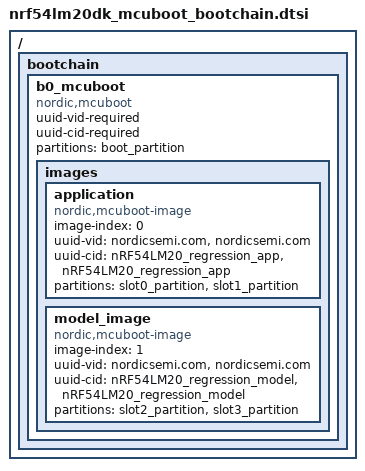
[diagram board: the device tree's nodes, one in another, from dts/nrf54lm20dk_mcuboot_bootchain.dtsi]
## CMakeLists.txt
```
#
# Copyright (c) 2025 Nordic Semiconductor ASA
#
# SPDX-License-Identifier: LicenseRef-Nordic-5-Clause
#

cmake_minimum_required(VERSION 3.20.0)

find_package(Zephyr REQUIRED HINTS $ENV{ZEPHYR_BASE})
project(nrf_edgeai_regression_sample)

include(${CMAKE_CURRENT_SOURCE_DIR}/../../../lib/model_ota/cmake/model_ota.cmake)

set(NEUTON_MODEL_DIR ${CMAKE_CURRENT_SOURCE_DIR}/src/nrf_edgeai_generated/Neuton)
set(AXON_MODEL_DIR ${CMAKE_CURRENT_SOURCE_DIR}/src/nrf_edgeai_generated/Axon)
set(NEUTON_MODEL_SRC ${NEUTON_MODEL_DIR}/nrf_edgeai_user_model.c)
set(AXON_MODEL_SRC ${AXON_MODEL_DIR}/nrf_edgeai_user_model.c)
set(AXON_MODEL_HEADER ${AXON_MODEL_DIR}/nrf_edgeai_user_model_axon.h)

target_include_directories(app PRIVATE include)

if(CONFIG_NRF_EDGEAI_REGRESSION_MODEL_AXON)
  if(NOT CONFIG_APP_MODEL_OTA)
    target_sources(app PRIVATE ${AXON_MODEL_SRC})
  endif()
  message(STATUS "Using Axon Edge AI model")
  target_include_directories(app PRIVATE ${AXON_MODEL_DIR})
else()
  if(NOT CONFIG_APP_MODEL_OTA)
    target_sources(app PRIVATE ${NEUTON_MODEL_SRC})
  endif()
  message(STATUS "Using Neuton Edge AI model")
  target_include_directories(app PRIVATE ${NEUTON_MODEL_DIR})
endif()

target_sources(app PRIVATE src/main.c)

if(CONFIG_APP_MODEL_OTA)
  if(CONFIG_NRF_EDGEAI_REGRESSION_MODEL_AXON)
    model_ota_edgeai_axon_model(
      TARGET regression
      SOLUTION_ID 36025
      MODEL_SRC ${AXON_MODEL_SRC}
      HEADER ${AXON_MODEL_HEADER}
      NAME regression
      VERSION 1.0.0
      PARTITION_NODELABEL model_storage
      UUID_CID nRF54LM20_regression_model
      UUID_VID nordicsemi.com
    )
  else()
    model_ota_edgeai_neuton_model(
      TARGET regression
      SOLUTION_ID 90508
      MODEL_SRC ${NEUTON_MODEL_SRC}
      PARTITION_NODELABEL model_storage
      NEURONS_CAP 2
      NAME regression
      VERSION 1.0.0
      UUID_CID nRF54LM20_regression_model
      UUID_VID nordicsemi.com
    )
  endif()

  model_ota_finalize()
endif()
```

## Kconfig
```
#
# Copyright (c) 2026 Nordic Semiconductor ASA
#
# SPDX-License-Identifier: LicenseRef-Nordic-5-Clause
#

menu "nRF Edge AI Regression sample"

choice NRF_EDGEAI_REGRESSION_MODEL
	prompt "Regression model backend"
	default NRF_EDGEAI_REGRESSION_MODEL_AXON if SOC_NRF54LM20B
	default NRF_EDGEAI_REGRESSION_MODEL_NEUTON
	help
	  Select which model implementation to use for the air quality regression sample.
	  Neuton runs on CPU; Axon uses the NPU and is only available on nRF54L20 (nrf54lm20b).

config NRF_EDGEAI_REGRESSION_MODEL_NEUTON
	bool "Neuton (CPU)"
	help
	  Use the Neuton model. Works on all nRF Edge AI supported boards.

config NRF_EDGEAI_REGRESSION_MODEL_AXON
	bool "Axon (NPU)"
	depends on SOC_NRF54LM20B
	select NRF_AXON
	help
	  Use the Axon model. Only available on nRF54L20 (nrf54lm20b) with Axon NPU.

endchoice

config APP_MODEL_OTA
	bool "Load regression model from a separate flash partition (model-only OTA)"
	select FLASH
	select FLASH_MAP
	select CRC
	select MODEL_OTA
	select MODEL_OTA_SMP
	help
	  When enabled, this sample does not ship a compiled-in regression model.
	  At boot, the model is loaded and validated from the model_storage flash
	  partition instead - independently of the application image.

	  Set via sysbuild as SB_CONFIG_APP_MODEL_OTA (see sysbuild_model_ota.conf).

if APP_MODEL_OTA

config APP_MODEL_OTA_NEUTON
	def_bool y
	depends on NRF_EDGEAI_REGRESSION_MODEL_NEUTON
	select MODEL_OTA_NEUTON

config APP_MODEL_OTA_AXON
	def_bool y
	depends on NRF_EDGEAI_REGRESSION_MODEL_AXON
	select MODEL_OTA_AXON

endif # APP_MODEL_OTA

endmenu

source "Kconfig.zephyr"
```

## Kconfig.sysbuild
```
#
# Copyright (c) 2026 Nordic Semiconductor
#
# SPDX-License-Identifier: LicenseRef-Nordic-5-Clause
#

config APP_MODEL_OTA
	bool "Load regression model from a separate flash partition (model-only OTA)"
	default n
	depends on BOOTLOADER_MCUBOOT
	help
	  When enabled, the sample loads the regression model from model_storage at boot
	  instead of using a compiled-in model. Propagated to the regression image as
	  CONFIG_APP_MODEL_OTA.

source "share/sysbuild/Kconfig"
```

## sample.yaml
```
sample:
  description: Sample showing nRF Edge AI regression model usage and results interpretation.
  name: nRF Edge AI Regression Sample
tests:
  sample.edgeai_regression:
    sysbuild: true
    build_only: true
    platform_allow:
      - nrf54l15dk/nrf54l05/cpuapp
      - nrf54l15dk/nrf54l10/cpuapp
      - nrf54l15dk/nrf54l15/cpuapp
      - nrf54h20dk/nrf54h20/cpuapp
      - nrf54lm20dk/nrf54lm20a/cpuapp
      - nrf54lm20dk/nrf54lm20b/cpuapp
    integration_platforms:
      - nrf54l15dk/nrf54l05/cpuapp
      - nrf54l15dk/nrf54l10/cpuapp
      - nrf54l15dk/nrf54l15/cpuapp
      - nrf54h20dk/nrf54h20/cpuapp
      - nrf54lm20dk/nrf54lm20a/cpuapp
      - nrf54lm20dk/nrf54lm20b/cpuapp
    tags:
      - nrf_edgeai_sample_regression
  sample.edgeai_regression.nrf54lm20dk:
    sysbuild: true
    build_only: false
    harness: console
    harness_config:
      type: multi_line
      ordered: true
      regex:
        - "nRF Edge AI runtime version: 2.2.0"
        - "--- Testing Model Air Quality predictions ---"
        - "Air quality - Predicted:.*Expected:.*absolute error"
        - "========== All test cases completed =========="
    platform_allow:
      - nrf54lm20dk/nrf54lm20a/cpuapp
      - nrf54lm20dk/nrf54lm20b/cpuapp
    integration_platforms:
      - nrf54lm20dk/nrf54lm20a/cpuapp
      - nrf54lm20dk/nrf54lm20b/cpuapp
    timeout: 30
    tags:
      - nrf_edgeai_sample_regression
```

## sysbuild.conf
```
# Copyright (c) 2026 Nordic Semiconductor ASA
#
# SPDX-License-Identifier: LicenseRef-Nordic-5-Clause

SB_CONFIG_BOOTLOADER_MCUBOOT=y
SB_CONFIG_MCUBOOT_UPDATEABLE_IMAGES=2
```

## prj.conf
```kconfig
#
# Copyright (c) 2025 Nordic Semiconductor ASA
#
# SPDX-License-Identifier: LicenseRef-Nordic-5-Clause
#

# nRF Edge AI
CONFIG_NRF_EDGEAI=y
# nRF Edge AI dependencies
CONFIG_FPU=y

# Model-only OTA update: by default (CONFIG_NRF_EDGEAI_REGRESSION_MODEL_OTA=y, see Kconfig)
# this sample loads the model from the model_storage flash partition instead of linking it
# into the application image. FLASH/FLASH_MAP/CRC/MODEL_OTA/MODEL_OTA_* are selected by that
# option together with the NRF_EDGEAI_REGRESSION_MODEL backend choice.

CONFIG_NCS_SAMPLES_DEFAULTS=y

# MCUboot: image 0 = dual-slot FW; image 1 = model (single- or dual-slot via sysbuild).
CONFIG_BOOTLOADER_MCUBOOT=y

# FW and model DFU over SMP (UART)
CONFIG_NET_BUF=y
CONFIG_ZCBOR=y
CONFIG_BASE64=y
CONFIG_STREAM_FLASH=y
CONFIG_MCUMGR=y
CONFIG_MCUMGR_MGMT_NOTIFICATION_HOOKS=y
CONFIG_UART_MCUMGR=y
CONFIG_MCUMGR_TRANSPORT_UART=y
CONFIG_IMG_MANAGER=y
CONFIG_MCUMGR_GRP_IMG=y
CONFIG_MCUMGR_GRP_IMG_STATUS_HOOKS=y
CONFIG_MCUMGR_GRP_IMG_UPLOAD_CHECK_HOOK=y
CONFIG_MCUMGR_GRP_OS=y
CONFIG_SYSTEM_WORKQUEUE_STACK_SIZE=2304
```

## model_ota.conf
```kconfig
#
# Copyright (c) 2026 Nordic Semiconductor ASA
#
# SPDX-License-Identifier: LicenseRef-Nordic-5-Clause
#
# Application options for partition-resident regression model (model-only OTA).
#
# Enable model OTA via sysbuild: pass sysbuild_model_ota.conf as SB_EXTRA_CONF_FILE.
# CONFIG_APP_MODEL_OTA is set from SB_CONFIG_APP_MODEL_OTA in sysbuild.cmake.

CONFIG_BOOTLOADER_MCUBOOT=y

# Flash + CRC (required by MCUMGR image DFU and UART transport)
CONFIG_FLASH=y
CONFIG_FLASH_MAP=y
CONFIG_CRC=y

# FW and model DFU over SMP (UART)
CONFIG_NET_BUF=y
CONFIG_ZCBOR=y
CONFIG_BASE64=y
CONFIG_STREAM_FLASH=y
CONFIG_MCUMGR=y
CONFIG_MCUMGR_MGMT_NOTIFICATION_HOOKS=y
CONFIG_UART_MCUMGR=y
CONFIG_MCUMGR_TRANSPORT_UART=y
CONFIG_IMG_MANAGER=y
CONFIG_MCUMGR_GRP_IMG=y
CONFIG_MCUMGR_GRP_IMG_STATUS_HOOKS=y
CONFIG_MCUMGR_GRP_IMG_UPLOAD_CHECK_HOOK=y
CONFIG_MCUMGR_GRP_OS=y
CONFIG_SYSTEM_WORKQUEUE_STACK_SIZE=4096
```

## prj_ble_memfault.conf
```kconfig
#
# Copyright (c) 2026 Nordic Semiconductor ASA
#
# SPDX-License-Identifier: LicenseRef-Nordic-5-Clause
#
# BLE SMP transport + Memfault MCUmgr group for gateway-driven model OTA.
# Include with EXTRA_CONF_FILE on top of prj.conf, for example:
#   west build ... -- -DEXTRA_CONF_FILE=prj_ble_memfault.conf

# Bluetooth LE peripheral for SMP (MCUmgr)
CONFIG_BT=y
CONFIG_BT_PERIPHERAL=y
CONFIG_BT_DEVICE_NAME="EdgeAI Regression"
# Use a static address so phones show a stable name while scanning.
CONFIG_BT_PRIVACY=n

# SMP characteristics must be readable without pairing for nRF Device Manager.
# (With BT_SMP=y the default is AUTHEN, which leaves SMP stuck on "initializing".)
CONFIG_MCUMGR_TRANSPORT_BT_PERM_RW=y

CONFIG_BT_L2CAP_TX_MTU=498
CONFIG_BT_BUF_ACL_RX_SIZE=502
CONFIG_BT_BUF_ACL_TX_SIZE=502
CONFIG_BT_CTLR_DATA_LENGTH_MAX=251

# SMP over BLE instead of the application UART (console logging stays on UART).
CONFIG_MCUMGR_TRANSPORT_UART=n
CONFIG_MCUMGR_TRANSPORT_BT=y
CONFIG_MCUMGR_TRANSPORT_BT_CONN_PARAM_CONTROL=y
CONFIG_MCUMGR_TRANSPORT_BT_REASSEMBLY=y
CONFIG_MCUMGR_TRANSPORT_NETBUF_SIZE=2475
CONFIG_MCUMGR_GRP_OS_MCUMGR_PARAMS=y
CONFIG_MCUMGR_TRANSPORT_WORKQUEUE_STACK_SIZE=4608

CONFIG_CRC=y
CONFIG_HEAP_MEM_POOL_SIZE=2048

# Bonding persistence for repeat gateway connections
CONFIG_SETTINGS=y
CONFIG_ZMS=y
CONFIG_BT_SETTINGS=y

# Memfault device identity exposed to gateways via MCUmgr group 128
CONFIG_MEMFAULT=y
CONFIG_MEMFAULT_USER_CONFIG_ENABLE=n
CONFIG_MEMFAULT_NCS_PROJECT_KEY=""
CONFIG_MEMFAULT_NCS_DEVICE_ID_STATIC=y
CONFIG_MEMFAULT_NCS_DEVICE_ID="edgeai-regression"
CONFIG_MEMFAULT_NCS_FW_TYPE="regression-model"
CONFIG_MEMFAULT_NCS_FW_VERSION_STATIC=y
CONFIG_MEMFAULT_NCS_FW_VERSION="1.0.0"
CONFIG_MEMFAULT_MCUMGR_GRP=y
CONFIG_MEMFAULT_NCS_HW_VERSION="nrf54lm20dk-ota-poc"

CONFIG_SYSTEM_WORKQUEUE_STACK_SIZE=4096
```

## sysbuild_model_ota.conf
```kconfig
#
# Copyright (c) 2026 Nordic Semiconductor ASA
#
# SPDX-License-Identifier: LicenseRef-Nordic-5-Clause
#
# Sysbuild options for partition-resident model. Pass as SB_EXTRA_CONF_FILE when building
# (model_ota.conf is applied to the regression image automatically from sysbuild.cmake).

SB_CONFIG_APP_MODEL_OTA=y
SB_CONFIG_BOOTLOADER_MCUBOOT=y
SB_CONFIG_MCUBOOT_UPDATEABLE_IMAGES=2
```

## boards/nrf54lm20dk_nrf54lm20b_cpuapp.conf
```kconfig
#
# Copyright (c) 2026 Nordic Semiconductor ASA
#
# SPDX-License-Identifier: LicenseRef-Nordic-5-Clause
#

CONFIG_NRF_AXON=y
CONFIG_NRF_AXON_INTERLAYER_BUFFER_SIZE=64
CONFIG_NRF_AXON_PSUM_BUFFER_SIZE=0

# Place nrf_axon_interlayer_buffer in the fixed-address memory region reserved in the board
# overlay (instead of plain .bss), so its address is identical in every build - required for
# model_ota's Axon loader to trust cmd_buffer's embedded references to it. See the overlay for
# why, and lib/model_ota/model_pkg_axon.c for the on-device check that would otherwise be the
# only thing catching a mismatch.
CONFIG_NRF_AXON_INTERLAYER_BUFFER_MEMREGION_NAME="AXON_INTERLAYER"
```

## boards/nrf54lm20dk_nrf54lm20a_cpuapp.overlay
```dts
/*
 * Copyright (c) 2026 Nordic Semiconductor ASA
 *
 * SPDX-License-Identifier: LicenseRef-Nordic-5-Clause
 */

#include "../dts/nrf54lm20dk_mcuboot_model.dtsi"
```

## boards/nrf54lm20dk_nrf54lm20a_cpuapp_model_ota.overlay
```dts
/*
 * Copyright (c) 2026 Nordic Semiconductor ASA
 *
 * SPDX-License-Identifier: LicenseRef-Nordic-5-Clause
 *
 * Two-image MCUboot layout (FW + regression model partition).
 * Use together with model_ota.conf.
 */

#include "../dts/nrf54lm20dk_mcuboot_model_ota.dtsi"
```

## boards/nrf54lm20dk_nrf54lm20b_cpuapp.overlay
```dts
/*
 * Copyright (c) 2026 Nordic Semiconductor ASA
 *
 * SPDX-License-Identifier: LicenseRef-Nordic-5-Clause
 */

&axon {
	status = "okay";
};

/*
 * This sample does not use mcuboot, so the board's second application slot
 * (slot1_partition) is unused. Repurpose it as a dedicated "model_storage" partition, sized
 * to comfortably fit future (larger) models too, instead of the much smaller default
 * "storage" partition.
 */
/delete-node/ &slot1_partition;

&cpuapp_rram {
	partitions {
		model_partition: partition@102000 {
			compatible = "zephyr,mapped-partition";
			label = "model_storage";
			reg = <0x102000 DT_SIZE_K(968)>;
		};
	};
};
```

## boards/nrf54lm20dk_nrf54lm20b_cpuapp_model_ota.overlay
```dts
/*
 * Copyright (c) 2026 Nordic Semiconductor ASA
 *
 * SPDX-License-Identifier: LicenseRef-Nordic-5-Clause
 *
 * Two-image MCUboot layout (FW + regression model partition).
 * Applied from sysbuild.cmake when SB_CONFIG_APP_MODEL_OTA is enabled.
 */

#include "../dts/nrf54lm20dk_mcuboot_model_ota.dtsi"
```

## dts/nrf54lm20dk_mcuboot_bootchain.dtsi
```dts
/*
 * Copyright (c) 2026 Nordic Semiconductor ASA
 *
 * SPDX-License-Identifier: LicenseRef-Nordic-5-Clause
 *
 * MCUboot bootchain for nRF54LM20 regression sample (image 0 = app, image 1 = model).
 * Include together with nrf54lm20dk_mcuboot_partitions_single.dtsi or the dual layout overlay.
 */

/ {
	bootchain {
		b0_mcuboot {
			compatible = "nordic,mcuboot";
			uuid-vid-required;
			uuid-cid-required;
			partitions = <&boot_partition>;

			images {
				application {
					compatible = "nordic,mcuboot-image";
					image-index = <0>;
					uuid-vid = "nordicsemi.com", "nordicsemi.com";
					uuid-cid = "nRF54LM20_regression_app", "nRF54LM20_regression_app";
					partitions = <&slot0_partition &slot1_partition>;
				};
				model_image {
					compatible = "nordic,mcuboot-image";
					image-index = <1>;
					uuid-vid = "nordicsemi.com", "nordicsemi.com";
					uuid-cid = "nRF54LM20_regression_model", "nRF54LM20_regression_model";
					partitions = <&slot2_partition &slot3_partition>;
				};
			};
		};
	};
};
```

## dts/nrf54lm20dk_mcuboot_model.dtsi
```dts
/*
 * Copyright (c) 2026 Nordic Semiconductor ASA
 *
 * SPDX-License-Identifier: LicenseRef-Nordic-5-Clause
 *
 * Default nRF54LM20 DK MCUboot + model_storage layout (single-slot model profile).
 *
 * Image 0: dual-slot firmware (swap-using-move, 684 kB slots).
 * Image 1: single-slot model (340 kB model_storage; slot2 and slot3 label the same region).
 *
 * For dual-slot model (separate slot2/slot3 with swap/revert), build with
 * SB_CONFIG_NRF_EDGEAI_REGRESSION_MODEL_SLOT_DUAL=y (see README.rst).
 *
 * Use in the application overlay and sysbuild/mcuboot/boards/ overlay.
 */

#include "nrf54lm20dk_mcuboot_partitions_single.dtsi"
#include "nrf54lm20dk_mcuboot_bootchain.dtsi"
```

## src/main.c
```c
/*
 * Copyright (c) 2025 Nordic Semiconductor ASA
 *
 * SPDX-License-Identifier: LicenseRef-Nordic-5-Clause
 */

/**
 * @file main.c
 * @brief Air Quality Prediction Regression Model
 *
 * This file implements a regression-based machine learning model for predicting air quality
 * levels based on gas sensor measurements and atmospheric conditions.
 *
 * @details
 * **Model Purpose:** Predict continuous air quality indices using multiple sensor inputs
 * for environmental monitoring and pollution prediction.
 *
 * **Input Features (9 total):**
 *   1. COGT - CO sensor reading (ppm or normalized units)
 *   2-6. PT08S1-5 - Five Pt-8 MOS metal oxide semiconductor sensors:
 *        - PT08S1: CO sensor
 *        - PT08S2: NMHC (non-methane hydrocarbons) sensor
 *        - PT08S3: NOx (nitrogen oxides) sensor
 *        - PT08S4: NO2 (nitrogen dioxide) sensor
 *        - PT08S5: O3 (ozone) sensor
 *   7. T - Temperature (Celsius)
 *   8. RH - Relative Humidity (%)
 *   9. AH - Absolute Humidity (kg/m³)
 *
 * **Output:** Single continuous value representing predicted air quality level
 *
 * **Applications:**
 *   - Environmental monitoring and air quality forecasting
 *   - Indoor air quality assessment
 *   - Pollution level prediction and public health alerts
 *   - Industrial emission monitoring
 *
 * **Validation Approach:**
 *   The model is validated against 29 test samples with known ground truth values.
 *   For each sample, the predicted value is compared with the expected value,
 *   and the absolute error is reported.
 */

#include <nrf_edgeai/nrf_edgeai.h>
#include "nrf_edgeai_user_model.h"

#include <zephyr/kernel.h>
#include <zephyr/logging/log.h>
#include <zephyr/sys/util.h>
#include <math.h>
#include <stdio.h>

#if IS_ENABLED(CONFIG_APP_MODEL_OTA)
#include <model_ota/model_ota_edgeai.h>
#include <model_ota/model_ota_smp.h>

#if defined(CONFIG_NRF_EDGEAI_REGRESSION_MODEL_AXON)
MODEL_OTA_EDGEAI_LOAD_DECL(36025);
#elif defined(CONFIG_NRF_EDGEAI_REGRESSION_MODEL_NEUTON)
MODEL_OTA_EDGEAI_LOAD_DECL(90508);
#endif
#endif

LOG_MODULE_REGISTER(regression, LOG_LEVEL_INF);

/**
 * @brief Model Configuration Constants
 *
 * These constants define the shape and size of the neural network model:
 * - USER_WINDOW_SIZE: Number of samples accumulated before running inference.
 *   A window size of 1 means inference occurs immediately after each sample.
 * - USER_UNIQ_INPUTS_NUM: Total number of input features to the model.
 *   Corresponds to: COGT (1) + PT08S sensors (5) + T, RH, AH (3) = 9 features
 * - USER_MODELS_OUTPUTS_NUM: Number of output values from the regression model.
 *   Set to 1 for single air quality prediction output.
 */
static const size_t USER_WINDOW_SIZE = 1;	 /* Samples per inference window */
static const size_t USER_UNIQ_INPUTS_NUM = 9;	 /* Gas sensor and environmental input features */
static const size_t USER_MODELS_OUTPUTS_NUM = 1; /* Single air quality prediction output */
static const flt32_t INVALID_PREDICTION_VALUE = -9999.0f; /* Invalid prediction indicator */

/**
 * @brief Test Dataset Structure and Values
 *
 * This structure defines the schema for test samples:
 * - COGT: CO sensor (main carbon monoxide detector)
 * - PT08S1-5: Five metal oxide semiconductor (MOS) sensors:
 *   * PT08S1: CO sensor output
 *   * PT08S2: NMHC (non-methane hydrocarbons) sensor
 *   * PT08S3: NOx (nitrogen oxides) sensor
 *   * PT08S4: NO2 (nitrogen dioxide) sensor
 *   * PT08S5: O3 (ozone) sensor
 * - T: Temperature in Celsius (affects pollutant concentration and sensor response)
 * - RH: Relative Humidity in percentage (influences sensor readings and pollutant behavior)
 * - AH: Absolute Humidity in kg/m³ (moisture content in air)
 * - target: Ground truth air quality value (used for validation)
 *
 * @note All sensor values are normalized or raw readings from the measurement device.
 * The 29 test samples cover various environmental conditions to validate model performance
 * across different temperature, humidity, and pollution levels.
 */
struct {
	flt32_t COGT;	/**< CO sensor reading */
	flt32_t PT08S1; /**< PT08 MOS sensor 1 (CO) */
	flt32_t PT08S2; /**< PT08 MOS sensor 2 (NMHC) */
	flt32_t PT08S3; /**< PT08 MOS sensor 3 (NOx) */
	flt32_t PT08S4; /**< PT08 MOS sensor 4 (NO2) */
	flt32_t PT08S5; /**< PT08 MOS sensor 5 (O3) */
	flt32_t T;	/**< Temperature in Celsius */
	flt32_t RH;	/**< Relative Humidity in percentage */
	flt32_t AH;	/**< Absolute Humidity in kg/m³ */
	flt32_t target; /**< Ground truth air quality value */
} static const USER_INPUT_DATA[] = {
	[0] = {2.7, 1146, 1125, 846, 1511, 1016, 33.4, 20.3, 1.027, 14.3},
	[1] = {3.3, 1272, 1328, 567, 2085, 1463, 19.6, 54.3, 1.2278, 21.1},
	[2] = {0.6, 919, 571, 1017, 1082, 521, 13.5, 63.8, 0.9801, 1.8},
	[3] = {1.7, 1162, 1019, 622, 1904, 1178, 27.9, 56.5, 2.0895, 11.1},
	[4] = {2.7, 1381, 1227, 595, 1903, 1845, 29.8, 33.1, 1.3693, 17.6},
	[5] = {1.1, 1010, 679, 854, 1046, 889, 5, 82.9, 0.73, 3.4},
	[6] = {1.9, 1055, 1037, 635, 1632, 1161, 25.3, 41.7, 1.3247, 11.6},
	[7] = {3.4, 1417, 1303, 635, 1964, 1752, 20.7, 40, 0.9639, 20.2},
	[8] = {2, 1273, 988, 563, 1387, 1257, 24.1, 33.3, 0.9881, 10.3},
	[9] = {4.8, 1435, 1429, 499, 2072, 1449, 21.7, 59.1, 1.5115, 25},
	[10] = {1, 1003, 635, 829, 1235, 711, 13.7, 80.6, 1.2528, 2.7},
	[11] = {1.3, 1259, 1152, 610, 1165, 1569, 8.2, 36.8, 0.4016, 15.1},
	[12] = {2.7, 1229, 1114, 598, 1723, 1247, 19.7, 0.73, 0.6708, 13.9},
	[13] = {2.8, 1261, 1258, 629, 1813, 1315, 43.4, 14.8, 1.2882, 18.6},
	[14] = {1.3, 997, 752, 837, 952, 724, 11.8, 34.4, 0.4758, 4.8},
	[15] = {1.3, 942, 846, 980, 1615, 905, 21.7, 50.8, 1.3019, 6.7},
	[16] = {0.6, 883, 518, 1135, 962, 606, 3.3, 84.5, 0.6612, 1.2},
	[17] = {3.2, 1174, 1264, 670, 1598, 1287, 28.9, 21.3, 0.8382, 18.8},
	[18] = {0.5, 748, 595, 1208, 1089, 677, 12.8, 0.598, 0.8801, 2.2},
	[19] = {1.4, 920, 783, 1046, 1550, 588, 24.5, 0.384, 1.1669, 5.4},
	[20] = {1.3, 906, 790, 893, 837, 642, 12.3, 19.3, 0.274, 5.5},
	[21] = {0.6, 882, 563, 978, 936, 660, 8.9, 0.527, 0.6034, 1.7},
	[22] = {3.4, 1403, 1443, 508, 2234, 1811, 25.2, 0.386, 1.2215, 25.6},
	[23] = {3.9, 1297, 1102, 507, 1375, 1583, 18.2, 0.363, 0.7487, 13.6},
	[24] = {1.3, 987, 800, 989, 1462, 658, 15.5, 0.571, 0.996, 5.7},
	[25] = {1.3, 869, 866, 1107, 1212, 596, 0.238, 0.145, 0.4222, 7.2},
	[26] = {3.2, 1336, 1340, 540, 2049, 1400, 21.3, 0.635, 1.5941, 21.6},
	[27] = {1, 955, 723, 1129, 1393, 559, 27.7, 0.258, 0.9467, 4.2},
	[28] = {4.3, 1373, 1364, 597, 2005, 1745, 33.7, 0.226, 1.1658, 22.5}};

/**
 * @brief Extract and Prepare Input Features for Model Inference
 *
 * This function extracts sensor readings and environmental parameters from a test sample
 * and arranges them into a buffer suitable for feeding to the neural network model.
 * The feature order must match the model's expected input layer ordering.
 *
 * @param[out] p_buffer          Pointer to buffer where input features will be stored.
 *                              Must have capacity for at least 9 floating-point values.
 * @param[in]  buffer_size       Size of the output buffer (must equal USER_UNIQ_INPUTS_NUM = 9).
 * @param[in]  sample_index      Index of the test sample to extract from USER_INPUT_DATA array.
 *
 * @return Ground truth air quality value for this sample, used for validation/comparison.
 *
 * @details
 * Feature arrangement in the buffer:
 *   [0] COGT   - CO sensor reading
 *   [1] PT08S1 - CO MOS sensor
 *   [2] PT08S2 - NMHC MOS sensor
 *   [3] PT08S3 - NOx MOS sensor
 *   [4] PT08S4 - NO2 MOS sensor
 *   [5] PT08S5 - O3 MOS sensor
 *   [6] T      - Temperature (Celsius)
 *   [7] RH     - Relative Humidity (%)
 *   [8] AH     - Absolute Humidity (kg/m³)
 *
 * The assertion ensures buffer_size validation to prevent buffer overflows.
 */
static flt32_t fill_features_buffer(flt32_t *p_buffer, const size_t buffer_size,
				    const size_t sample_index)
{
	/* Verify buffer has correct capacity for all 9 input features */
	__ASSERT_NO_MSG(buffer_size == USER_UNIQ_INPUTS_NUM);

	/* Extract and arrange sensor readings into the input buffer */
	p_buffer[0] = USER_INPUT_DATA[sample_index].COGT;   /* CO sensor */
	p_buffer[1] = USER_INPUT_DATA[sample_index].PT08S1; /* PT08 CO sensor */
	p_buffer[2] = USER_INPUT_DATA[sample_index].PT08S2; /* PT08 NMHC sensor */
	p_buffer[3] = USER_INPUT_DATA[sample_index].PT08S3; /* PT08 NOx sensor */
	p_buffer[4] = USER_INPUT_DATA[sample_index].PT08S4; /* PT08 NO2 sensor */
	p_buffer[5] = USER_INPUT_DATA[sample_index].PT08S5; /* PT08 O3 sensor */
	p_buffer[6] = USER_INPUT_DATA[sample_index].T;	    /* Temperature */
	p_buffer[7] = USER_INPUT_DATA[sample_index].RH;	    /* Relative Humidity */
	p_buffer[8] = USER_INPUT_DATA[sample_index].AH;	    /* Absolute Humidity */

	/* Return ground truth value for later comparison with prediction */
	return USER_INPUT_DATA[sample_index].target;
}

/**
 * @brief Run Air Quality Regression Model Inference
 *
 * This function executes the neural network model to predict air quality based on
 * provided sensor inputs. The process follows the Edge AI inference pipeline:
 * 1. Feed sensor data into the model's input window
 * 2. Execute the neural network computation when the window is full
 * 3. Extract the continuous air quality prediction from the regression output
 *
 * @param[in] p_user_model      Pointer to the initialized Edge AI model instance.
 * @param[in] p_input_features  Array containing 9 sensor/environmental input values.
 * @param[in] features_num      Number of features in the input array (must be 9).
 *
 * @return Predicted air quality value as a floating-point number.
 *         Returns -1000.0 (invalid sentinel value) if inference fails or encounters errors.
 *
 * @details
 * **Inference Pipeline:**
 * - The model uses a 1-sample window (USER_WINDOW_SIZE=1), so inference occurs immediately
 *   after feeding a single sensor reading.
 * - Input features are processed through the neural network layers trained on historical
 *   air quality data.
 * - The output is a continuous value representing the predicted air quality level,
 *   suitable for direct comparison with ground truth measurements.
 *
 * **Error Handling:**
 * - Returns an invalid sentinel value (INVALID_PREDICTION_VALUE) if any step fails, allowing the
 * caller to detect and handle prediction failures gracefully.
 * - Assertions validate that the model outputs exactly 1 value as expected for this
 *   regression task.
 */
static flt32_t model_predict(nrf_edgeai_t *p_user_model, flt32_t *p_input_features,
			     size_t features_num)
{
	nrf_edgeai_err_t res;
	/* Invalid default value for error detection */
	flt32_t model_prediction = INVALID_PREDICTION_VALUE;

	/* Step 1: Feed sensor inputs into the model's preprocessing pipeline */
	res = nrf_edgeai_feed_inputs(p_user_model, p_input_features, features_num);

	if (res == NRF_EDGEAI_ERR_UNAVAILABLE) {
		return INVALID_PREDICTION_VALUE;
	}

	if (res == NRF_EDGEAI_ERR_SUCCESS) {
		res = nrf_edgeai_run_inference(p_user_model);

		if (res == NRF_EDGEAI_ERR_UNAVAILABLE) {
			return INVALID_PREDICTION_VALUE;
		}

		/* Step 3: Extract the regression output if inference was successful */
		if (res == NRF_EDGEAI_ERR_SUCCESS) {
			/* Access the regression model output (continuous value prediction) */
			const flt32_t *p_output = p_user_model->decoded_output.regression.p_outputs;

			__ASSERT_NO_MSG(p_user_model->decoded_output.regression.outputs_num ==
					USER_MODELS_OUTPUTS_NUM);

			/* Extract the single air quality prediction value */
			model_prediction = p_output[0];
		}
	}

	return model_prediction;
}

static void run_inference_loop(nrf_edgeai_t *p_user_model)
{
	flt32_t input_features[USER_UNIQ_INPUTS_NUM];
	const size_t num_input_samples = ARRAY_SIZE(USER_INPUT_DATA);

	for (size_t i = 0; i < num_input_samples; i++) {
		flt32_t ground_truth =
			fill_features_buffer(input_features, USER_UNIQ_INPUTS_NUM, i);
		flt32_t predicted_value =
			model_predict(p_user_model, input_features, USER_UNIQ_INPUTS_NUM);
		flt32_t abs_err = fabsf(predicted_value - ground_truth);

		LOG_INF("Air quality - Predicted: %f, Expected: %f, absolute error %f",
			(double)predicted_value, (double)ground_truth, (double)abs_err);
	}

	LOG_INF("========== All test cases completed ==========");
}

int main(void)
{
	/* Retrieve the generated neural network model for air quality prediction */
#if defined(CONFIG_APP_MODEL_OTA)
	enum model_image_result load_rc;
	nrf_edgeai_t *p_user_model;

#if defined(CONFIG_NRF_EDGEAI_REGRESSION_MODEL_AXON)
	load_rc = nrf_edgeai_load_user_model_36025(&p_user_model);
#elif defined(CONFIG_NRF_EDGEAI_REGRESSION_MODEL_NEUTON)
	load_rc = nrf_edgeai_load_user_model_90508(&p_user_model);
#endif

	if (load_rc != MODEL_IMAGE_OK || p_user_model == NULL) {
		LOG_ERR("No usable regression model - see model_storage flashing instructions in "
			"README.rst");
		return -ENOENT;
	}
#else
	nrf_edgeai_t *p_user_model = nrf_edgeai_user_model();

	__ASSERT_NO_MSG(p_user_model != NULL);
#endif

	/* Validate model configuration: ensure the generated model matches expected parameters */
	__ASSERT_NO_MSG(nrf_edgeai_input_window_size(p_user_model) == USER_WINDOW_SIZE);
	__ASSERT_NO_MSG(nrf_edgeai_uniq_inputs_num(p_user_model) == USER_UNIQ_INPUTS_NUM);
	__ASSERT_NO_MSG(nrf_edgeai_model_outputs_num(p_user_model) == USER_MODELS_OUTPUTS_NUM);

	/* Initialize the Edge AI runtime to prepare the model for inference execution */
	nrf_edgeai_err_t res = nrf_edgeai_init(p_user_model);

	__ASSERT_NO_MSG(res == NRF_EDGEAI_ERR_SUCCESS);

	nrf_edgeai_rt_version_t v = nrf_edgeai_runtime_version();
	LOG_INF("nRF Edge AI runtime version: %d.%d.%d", v.field.major, v.field.minor,
		v.field.patch);

	LOG_INF("--- Testing Model Air Quality predictions ---");
	if (p_user_model->model.type == NRF_EDGEAI_MODEL_AXON) {
		LOG_INF("Using Axon model");
	} else {
		LOG_INF("Using Neuton model");
	}

	while (1) {
#if IS_ENABLED(CONFIG_APP_MODEL_OTA)
		/* Application policy: idle after upload until the operator resets the device. */
		if (model_ota_smp_is_pending_reset()) {
			k_sleep(K_FOREVER);
			continue;
		}
#endif
		run_inference_loop(p_user_model);
		k_sleep(K_MSEC(5000));
	}

	return 0;
}
```

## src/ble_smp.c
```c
/*
 * Copyright (c) 2026 Nordic Semiconductor ASA
 *
 * SPDX-License-Identifier: LicenseRef-Nordic-5-Clause
 *
 * BLE advertising for MCUmgr SMP, with Nordic-recommended init order:
 * bt_enable() -> settings_load() -> start advertising.
 */

#include <zephyr/bluetooth/bluetooth.h>
#include <zephyr/bluetooth/conn.h>
#include <zephyr/bluetooth/hci.h>
#include <zephyr/mgmt/mcumgr/transport/smp_bt.h>
#include <zephyr/settings/settings.h>
#include <zephyr/logging/log.h>

LOG_MODULE_REGISTER(regression_ble, LOG_LEVEL_INF);

static struct k_work advertise_work;

#define DEVICE_NAME     CONFIG_BT_DEVICE_NAME
#define DEVICE_NAME_LEN (sizeof(DEVICE_NAME) - 1)

static const struct bt_data ad[] = {
	BT_DATA_BYTES(BT_DATA_FLAGS, (BT_LE_AD_GENERAL | BT_LE_AD_NO_BREDR)),
	BT_DATA_BYTES(BT_DATA_UUID128_ALL, SMP_BT_SVC_UUID_VAL),
};

static const struct bt_data sd[] = {
	BT_DATA(BT_DATA_NAME_COMPLETE, DEVICE_NAME, DEVICE_NAME_LEN),
};

static void advertise(struct k_work *work)
{
	int rc;

	rc = bt_le_adv_start(BT_LE_ADV_CONN_FAST_1, ad, ARRAY_SIZE(ad), sd, ARRAY_SIZE(sd));
	if (rc != 0) {
		LOG_ERR("Advertising failed to start (rc %d)", rc);
		return;
	}

	LOG_INF("Advertising successfully started");
}

static void connected(struct bt_conn *conn, uint8_t err)
{
	if (err != 0) {
		LOG_ERR("Connection failed, err 0x%02x %s", err, bt_hci_err_to_str(err));
		k_work_submit(&advertise_work);
	} else {
		LOG_INF("Connected");
	}
}

static void disconnected(struct bt_conn *conn, uint8_t reason)
{
	LOG_INF("Disconnected, reason 0x%02x %s", reason, bt_hci_err_to_str(reason));
}

static void on_conn_recycled(void)
{
	k_work_submit(&advertise_work);
}

BT_CONN_CB_DEFINE(conn_callbacks) = {
	.connected = connected,
	.disconnected = disconnected,
	.recycled = on_conn_recycled,
};

void start_smp_bluetooth_adverts(void)
{
	int rc;

	k_work_init(&advertise_work, advertise);

	rc = bt_enable(NULL);
	if (rc != 0) {
		LOG_ERR("Bluetooth enable failed: %d", rc);
		return;
	}

#if defined(CONFIG_SETTINGS)
	rc = settings_load();
	if (rc != 0) {
		LOG_ERR("settings_load failed: %d", rc);
	}
#endif

	k_work_submit(&advertise_work);
}
```

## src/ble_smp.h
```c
/*
 * Copyright (c) 2026 Nordic Semiconductor ASA
 *
 * SPDX-License-Identifier: LicenseRef-Nordic-5-Clause
 */

#ifndef REGRESSION_BLE_SMP_H_
#define REGRESSION_BLE_SMP_H_

void start_smp_bluetooth_adverts(void);

#endif /* REGRESSION_BLE_SMP_H_ */
```

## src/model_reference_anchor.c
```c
/*
 * Copyright (c) 2026 Nordic Semiconductor ASA
 *
 * SPDX-License-Identifier: LicenseRef-Nordic-5-Clause
 */

/*
 * Reference-build-only translation unit (see CONFIG_NRF_EDGEAI_REGRESSION_REFERENCE_BUILD in
 * Kconfig): never compiled into the deployed app, which no longer links in the generated Axon
 * model sources - it loads its model from the model_storage flash partition at runtime instead.
 * Packaging a model update still needs a real link address for the model's constants blob (see
 * package_base in model_pkg_axon_header), which only exists in a build that actually references
 * those sources.
 *
 * Including the header here is enough to make the compiler emit model_axon_user_instance_36025,
 * cmd_buffer_axon_user_instance_36025 and axon_model_const_axon_user_instance_36025;
 * CMakeLists.txt's toolchain_ld_force_undefined_symbols(model_axon_user_instance_36025) then
 * keeps that symbol's section (and, transitively via its own relocations to the other two,
 * theirs as well) alive through the linker's --gc-sections, since nothing else in this
 * reference-only image references any of them. This build does nothing else and is never
 * flashed as the application - see README.rst.
 */
#include <assert.h>
#include <stddef.h>
#include <stdint.h>

#include <axon/nrf_axon_platform.h>
#include <drivers/axon/nrf_axon_nn_infer.h>

#include "nrf_edgeai_user_model_axon.h"
```

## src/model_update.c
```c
/*
 * Copyright (c) 2026 Nordic Semiconductor ASA
 *
 * SPDX-License-Identifier: LicenseRef-Nordic-5-Clause
 */

#include <model_ota/model_ota_smp.h>

#include <zephyr/logging/log.h>
#include <zephyr/sys/util.h>

#include "model_update.h"

LOG_MODULE_REGISTER(model_update);

static const struct model_ota_smp_slot regression_smp_slots[] = {
	{
		.image_index = REGRESSION_MODEL_IMAGE_INDEX,
		.name = "REGRESSION",
	},
};

static void model_update_upload_notify(bool active)
{
	if (active) {
		return;
	}

	if (model_ota_smp_is_pending_reset()) {
		LOG_WRN("Model upload complete - reset required to load new model");
	}
}

int model_update_init(void)
{
	model_ota_smp_set_upload_notify_cb(model_update_upload_notify);

	int err = model_ota_smp_init(regression_smp_slots, ARRAY_SIZE(regression_smp_slots));

	if (err != 0) {
		LOG_ERR("Model SMP coordination init failed (err %d, slots %u, max %u)", err,
			(unsigned)ARRAY_SIZE(regression_smp_slots),
			(unsigned)CONFIG_MODEL_OTA_SMP_MAX_SLOTS);
	}

	return err;
}

bool model_update_blocks_inference(void)
{
	return model_ota_smp_blocks_inference(REGRESSION_MODEL_IMAGE_INDEX);
}

bool model_update_is_pending_reset(void)
{
	return model_ota_smp_is_pending_reset();
}
```

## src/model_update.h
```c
/*
 * Copyright (c) 2026 Nordic Semiconductor ASA
 *
 * SPDX-License-Identifier: LicenseRef-Nordic-5-Clause
 */

#pragma once

#include <stdbool.h>

/** MCUboot updateable image index for the regression model. */
#define REGRESSION_MODEL_IMAGE_INDEX 1

/**
 * Register SMP upload hooks that pause inference during model DFU.
 *
 * @retval 0 on success.
 * @retval Negative errno from model_ota_smp_init() on failure.
 */
int model_update_init(void);

/** True while a regression model SMP upload is active or pending reset. */
bool model_update_blocks_inference(void);

/** True after a model SMP upload finished and a reset is required. */
bool model_update_is_pending_reset(void);
```

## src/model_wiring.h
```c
/*
 * Copyright (c) 2026 Nordic Semiconductor ASA
 *
 * SPDX-License-Identifier: LicenseRef-Nordic-5-Clause
 */

#ifndef MODEL_WIRING_H_
#define MODEL_WIRING_H_

#include <nrf_edgeai/nrf_edgeai.h>

/**
 * @brief Get the regression model to run inference against.
 *
 * Implemented by exactly one of model_wiring_neuton.c / model_wiring_axon.c, selected at build
 * time by the NRF_EDGEAI_REGRESSION_MODEL Kconfig choice, so main.c stays backend-agnostic.
 *
 * With CONFIG_NRF_EDGEAI_REGRESSION_MODEL_OTA=y (the default), this loads and validates a
 * model package from the model_storage flash partition on every call.
 *
 * With CONFIG_NRF_EDGEAI_REGRESSION_MODEL_OTA=n, the model is compiled directly into the
 * application image instead: this always returns the same pointer to it, and never NULL.
 *
 * @return Pointer to a ready-to-use nrf_edgeai_t on success, or NULL if model_storage does not
 *         currently hold a valid package for this backend (CONFIG_NRF_EDGEAI_REGRESSION_MODEL_OTA=y
 *         only).
 */
nrf_edgeai_t *model_ota_load(void);

#endif /* MODEL_WIRING_H_ */
```

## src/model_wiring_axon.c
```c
/*
 * Copyright (c) 2026 Nordic Semiconductor ASA
 *
 * SPDX-License-Identifier: LicenseRef-Nordic-5-Clause
 */

#include "model_wiring.h"

#if defined(CONFIG_NRF_EDGEAI_REGRESSION_MODEL_OTA)
#include <model_ota/model_pkg.h>

#include <zephyr/storage/flash_map.h>
#endif

#include <axon/nrf_axon_platform.h>
#include <drivers/axon/nrf_axon_nn_infer.h>
#include <nrf_edgeai/nrf_edgeai_platform.h>
#include <nrf_edgeai/rt/private/nrf_edgeai_interfaces.h>

#if !defined(CONFIG_NRF_EDGEAI_REGRESSION_MODEL_OTA)
#include <assert.h> /* for the static_assert()s in the generated header below */

/* Needs the axon platform/driver headers above (nrf_axon_interlayer_buffer,
 * NRF_AXON_PLATFORM_BITWIDTH_UNSIGNED_TYPE, ...) to already be visible.
 */
#include "nrf_edgeai_generated/Axon/nrf_edgeai_user_model_axon.h"
#endif

#include <zephyr/logging/log.h>

LOG_MODULE_REGISTER(model_wiring_axon, LOG_LEVEL_INF);

#define EDGEAI_SOLUTION_ID_STR          "36025"
#define EDGEAI_RUNTIME_VERSION_COMBINED 0x00000202

/* Same 9 sensor/environmental features and scaling as the Neuton backend - the input pipeline
 * is shared between backends and is part of the application, not the updatable model package.
 */
#define INPUT_UNIQ_FEATURES_NUM 9

static const flt32_t INPUT_FEATURES_SCALE_MIN[INPUT_UNIQ_FEATURES_NUM] = {
	0.1000000f,  647.0000000f, 387.0000000f, 322.0000000f, 559.0000000f,
	225.0000000f, -1.3000000f, 9.1999998f,   0.1847000f,
};
static const flt32_t INPUT_FEATURES_SCALE_MAX[INPUT_UNIQ_FEATURES_NUM] = {
	11.8999996f,  2040.0000000f, 2214.0000000f, 2683.0000000f, 2775.0000000f,
	2523.0000000f, 44.5999985f,  88.6999969f,   2.1805999f,
};

/* Axon's own output dequantization already yields the final regression value, so no further
 * rescaling is needed here - this identity [0,1] range matches the compiled-in Axon model this
 * backend replaces.
 */
static const flt32_t MODEL_OUTPUT_SCALE_MIN[] = {0.0000000f};
static const flt32_t MODEL_OUTPUT_SCALE_MAX[] = {1.0000000f};

#define MODEL_OUTPUTS_NUM 1

#if defined(CONFIG_NRF_EDGEAI_REGRESSION_MODEL_OTA)
/*
 * The model itself is *not* compiled in: this is only populated (by model_pkg_load_axon()) once
 * a valid package has been read from the model_storage flash partition.
 */
static nrf_axon_nn_compiled_model_s model_instance_;
#define MODEL_INSTANCE (&model_instance_)
#else
/* Compiled directly into the application image - this sample's original pre-model-OTA
 * behavior. model_axon_user_instance_36025 is defined by the generated model header included
 * above.
 */
#define MODEL_INSTANCE (&model_axon_user_instance_36025)
#endif

static flt32_t model_outputs_[MODEL_OUTPUTS_NUM];

static nrf_edgeai_t nrf_edgeai_ = {
	.metadata.p_solution_id = EDGEAI_SOLUTION_ID_STR,
	.metadata.version.combined = EDGEAI_RUNTIME_VERSION_COMBINED,

	.input.p_used_for_lags_mask = NULL,
	.input.p_usage_mask = NULL,
	.input.type = NRF_EDGEAI_INPUT_F32,
	.input.unique_num = INPUT_UNIQ_FEATURES_NUM,
	.input.unique_num_used = INPUT_UNIQ_FEATURES_NUM,
	.input.unique_scales_num = INPUT_UNIQ_FEATURES_NUM,
	.input.window_size = 1,
	.input.window_shift = 0,
	.input.subwindow_num = 0,
	.input.window_memory.p_void = NULL,
	.input.p_window_ctx = NULL,
	.input.scale.f32 =
		{
			.p_min = INPUT_FEATURES_SCALE_MIN,
			.p_max = INPUT_FEATURES_SCALE_MAX,
		},

	.p_dsp = NULL,

	.model.type = NRF_EDGEAI_MODEL_AXON,
	.model.task = NRF_EDGEAI_TASK_REGRESSION,
	.model.instance.p_void = MODEL_INSTANCE,
	.model.output.memory.p_void = model_outputs_,
	.model.output.num = MODEL_OUTPUTS_NUM,
	.model.uses_as_input.all = 1,

	.interfaces.input_init = nrf_edgeai_input_init_no_window,
	.interfaces.feed_inputs = nrf_edgeai_input_feed_no_window,
	.interfaces.process_features = nrf_edgeai_process_features_scale_vector_f32_f32,
	.interfaces.init_inference = nrf_edgeai_init_inference_axon,
	.interfaces.run_inference = nrf_edgeai_run_inference_axon,
	.interfaces.propagate_outputs = nrf_edgeai_output_dequantize_axon_q8_f32,
	.interfaces.decode_outputs = nrf_edgeai_output_decode_regression_f32,

	.decoded_output.regression.meta.p_scale_min = MODEL_OUTPUT_SCALE_MIN,
	.decoded_output.regression.meta.p_scale_max = MODEL_OUTPUT_SCALE_MAX,
};

#if defined(CONFIG_NRF_EDGEAI_REGRESSION_MODEL_OTA)

nrf_edgeai_t *model_ota_load(void)
{
	struct model_pkg_axon_info info;
	int err;

	err = model_pkg_load_axon(PARTITION_ID(model_partition),
				   (const uint8_t *)PARTITION_ADDRESS(model_partition),
				   &model_instance_, &info);
	if (err != MODEL_PKG_OK) {
		LOG_ERR("No usable model in model_storage (err %d)", err);
		return NULL;
	}

	LOG_INF("Active model: '%s' version 0x%08x (%u cmd words, %u B const)", info.name,
		info.version, info.cmd_buffer_len, info.model_const_size);

	return &nrf_edgeai_;
}

#else

nrf_edgeai_t *model_ota_load(void)
{
	return &nrf_edgeai_;
}

#endif /* CONFIG_NRF_EDGEAI_REGRESSION_MODEL_OTA */
```

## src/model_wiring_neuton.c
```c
/*
 * Copyright (c) 2026 Nordic Semiconductor ASA
 *
 * SPDX-License-Identifier: LicenseRef-Nordic-5-Clause
 */

#include "model_wiring.h"

#if defined(CONFIG_NRF_EDGEAI_REGRESSION_MODEL_OTA)
#include <model_ota/model_pkg.h>
#endif

#include <nrf_edgeai/nrf_edgeai_platform.h>
#include <nrf_edgeai/rt/private/nrf_edgeai_interfaces.h>

#include <zephyr/logging/log.h>
#include <zephyr/sys/util.h>

LOG_MODULE_REGISTER(model_wiring_neuton, LOG_LEVEL_INF);

/* Air-quality regression inputs: 9 sensor/environmental features. The feature extraction /
 * input-scaling pipeline is part of the application, not the updatable model package: per the
 * model-OTA constraints this PoC is based on, it cannot be changed by a model-only update.
 */
#define INPUT_UNIQ_FEATURES_NUM 9

static const flt32_t INPUT_FEATURES_SCALE_MIN[INPUT_UNIQ_FEATURES_NUM] = {
	0.1000000f,  647.0000000f, 387.0000000f, 322.0000000f, 559.0000000f,
	225.0000000f, -1.3000000f, 9.1999998f,   0.1847000f,
};
static const flt32_t INPUT_FEATURES_SCALE_MAX[INPUT_UNIQ_FEATURES_NUM] = {
	11.8999996f,  2040.0000000f, 2214.0000000f, 2683.0000000f, 2775.0000000f,
	2523.0000000f, 44.5999985f,  88.6999969f,   2.1805999f,
};

#define MODEL_OUTPUTS_NUM 1

#if defined(CONFIG_NRF_EDGEAI_REGRESSION_MODEL_OTA)

#define EDGEAI_SOLUTION_ID_STR          "36025"
#define EDGEAI_RUNTIME_VERSION_COMBINED 0x00000202

/*
 * The model itself is *not* compiled in: these are only populated (by model_pkg_load_neuton())
 * once a valid package has been read from the model_storage flash partition.
 */
static nrf_edgeai_model_neuton_t model_instance_;
static flt32_t model_neurons_[CONFIG_MODEL_OTA_MAX_NEURONS];
static flt32_t model_outputs_[MODEL_OUTPUTS_NUM];

static nrf_edgeai_t nrf_edgeai_ = {
	.metadata.p_solution_id = EDGEAI_SOLUTION_ID_STR,
	.metadata.version.combined = EDGEAI_RUNTIME_VERSION_COMBINED,

	.input.p_used_for_lags_mask = NULL,
	.input.p_usage_mask = NULL,
	.input.type = NRF_EDGEAI_INPUT_F32,
	.input.unique_num = INPUT_UNIQ_FEATURES_NUM,
	.input.unique_num_used = INPUT_UNIQ_FEATURES_NUM,
	.input.unique_scales_num = INPUT_UNIQ_FEATURES_NUM,
	.input.window_size = 1,
	.input.window_shift = 0,
	.input.subwindow_num = 0,
	.input.window_memory.p_void = NULL,
	.input.p_window_ctx = NULL,
	.input.scale.f32 =
		{
			.p_min = INPUT_FEATURES_SCALE_MIN,
			.p_max = INPUT_FEATURES_SCALE_MAX,
		},

	.p_dsp = NULL,

	.model.type = NRF_EDGEAI_MODEL_NEUTON,
	.model.task = NRF_EDGEAI_TASK_REGRESSION,
	.model.instance.p_void = &model_instance_,
	.model.output.memory.p_void = model_outputs_,
	.model.output.num = MODEL_OUTPUTS_NUM,
	.model.uses_as_input.all = 1,

	.interfaces.input_init = nrf_edgeai_input_init_no_window,
	.interfaces.feed_inputs = nrf_edgeai_input_feed_no_window,
	.interfaces.process_features = nrf_edgeai_process_features_scale_vector_f32_f32,
	.interfaces.init_inference = nrf_edgeai_init_inference_neuton,
	.interfaces.run_inference = nrf_edgeai_run_inference_neuton_f32,
	.interfaces.propagate_outputs = nrf_edgeai_output_propagate_neuton_f32,
	.interfaces.decode_outputs = nrf_edgeai_output_decode_regression_f32,

	/* Filled in by model_ota_load() once a model package has been validated. */
	.decoded_output.regression.meta.p_scale_min = NULL,
	.decoded_output.regression.meta.p_scale_max = NULL,
};

nrf_edgeai_t *model_ota_load(void)
{
	struct model_pkg_neuton_info info;
	int err;

	err = model_pkg_load_neuton(&model_instance_, model_neurons_, ARRAY_SIZE(model_neurons_),
				     &info);
	if (err != MODEL_PKG_OK) {
		LOG_ERR("No usable model in model_storage (err %d)", err);
		return NULL;
	}

	nrf_edgeai_.decoded_output.regression.meta.p_scale_min = info.output_scale_min;
	nrf_edgeai_.decoded_output.regression.meta.p_scale_max = info.output_scale_max;

	LOG_INF("Active model: '%s' version 0x%08x (%u neurons, %u weights)", info.name,
		info.version, info.neurons_num, info.weights_num);

	return &nrf_edgeai_;
}

#else /* !CONFIG_NRF_EDGEAI_REGRESSION_MODEL_OTA: compiled-in model (solution 90508), no
       * model_storage partition or runtime loading - this sample's original pre-model-OTA
       * behavior.
       */

#define EDGEAI_SOLUTION_ID_STR          "90508"
#define EDGEAI_RUNTIME_VERSION_COMBINED 0x00000202

#define MODEL_NEURONS_NUM 2
#define MODEL_WEIGHTS_NUM 4

static const flt32_t MODEL_WEIGHTS[MODEL_WEIGHTS_NUM] = {0.5644180f, 0.1098376f, 0.9692999f,
							  -0.4583102f};
static const uint16_t MODEL_NEURONS_LINKS[MODEL_WEIGHTS_NUM] = {2, 9, 0, 9};
static const uint16_t MODEL_NEURON_INTERNAL_LINKS_NUM[MODEL_NEURONS_NUM] = {0, 3};
static const uint16_t MODEL_NEURON_EXTERNAL_LINKS_NUM[MODEL_NEURONS_NUM] = {2, 4};
static const flt32_t MODEL_NEURON_ACTIVATION_WEIGHTS[MODEL_NEURONS_NUM] = {20.0000000f,
									   10.0783634f};
static const uint8_t MODEL_NEURON_ACTIVATION_TYPE_MASK[] = {0x1};
static const uint16_t MODEL_OUTPUT_NEURONS_INDICES[MODEL_OUTPUTS_NUM] = {1};
static const flt32_t MODEL_OUTPUT_SCALE_MIN[MODEL_OUTPUTS_NUM] = {0.2000000f};
static const flt32_t MODEL_OUTPUT_SCALE_MAX[MODEL_OUTPUTS_NUM] = {63.7000008f};

static flt32_t model_neurons_[MODEL_NEURONS_NUM];
static flt32_t model_outputs_[MODEL_OUTPUTS_NUM];

static const nrf_edgeai_model_neuton_t model_instance_ = {
	.meta.p_neuron_internal_links_num = MODEL_NEURON_INTERNAL_LINKS_NUM,
	.meta.p_neuron_external_links_num = MODEL_NEURON_EXTERNAL_LINKS_NUM,
	.meta.p_output_neurons_indices = MODEL_OUTPUT_NEURONS_INDICES,
	.meta.p_neuron_links = MODEL_NEURONS_LINKS,
	.meta.p_neuron_act_type_mask = MODEL_NEURON_ACTIVATION_TYPE_MASK,
	.meta.outputs_num = MODEL_OUTPUTS_NUM,
	.meta.neurons_num = MODEL_NEURONS_NUM,
	.meta.weights_num = MODEL_WEIGHTS_NUM,
	.params.f32 =
		{
			.p_weights = MODEL_WEIGHTS,
			.p_act_weights = MODEL_NEURON_ACTIVATION_WEIGHTS,
			.p_neurons = model_neurons_,
		},
};

static nrf_edgeai_t nrf_edgeai_ = {
	.metadata.p_solution_id = EDGEAI_SOLUTION_ID_STR,
	.metadata.version.combined = EDGEAI_RUNTIME_VERSION_COMBINED,

	.input.p_used_for_lags_mask = NULL,
	.input.p_usage_mask = NULL,
	.input.type = NRF_EDGEAI_INPUT_F32,
	.input.unique_num = INPUT_UNIQ_FEATURES_NUM,
	.input.unique_num_used = INPUT_UNIQ_FEATURES_NUM,
	.input.unique_scales_num = INPUT_UNIQ_FEATURES_NUM,
	.input.window_size = 1,
	.input.window_shift = 0,
	.input.subwindow_num = 0,
	.input.window_memory.p_void = NULL,
	.input.p_window_ctx = NULL,
	.input.scale.f32 =
		{
			.p_min = INPUT_FEATURES_SCALE_MIN,
			.p_max = INPUT_FEATURES_SCALE_MAX,
		},

	.p_dsp = NULL,

	.model.type = NRF_EDGEAI_MODEL_NEUTON,
	.model.task = NRF_EDGEAI_TASK_REGRESSION,
	.model.instance.p_void = &model_instance_,
	.model.output.memory.p_void = model_outputs_,
	.model.output.num = MODEL_OUTPUTS_NUM,
	.model.uses_as_input.all = 1,

	.interfaces.input_init = nrf_edgeai_input_init_no_window,
	.interfaces.feed_inputs = nrf_edgeai_input_feed_no_window,
	.interfaces.process_features = nrf_edgeai_process_features_scale_vector_f32_f32,
	.interfaces.init_inference = nrf_edgeai_init_inference_neuton,
	.interfaces.run_inference = nrf_edgeai_run_inference_neuton_f32,
	.interfaces.propagate_outputs = nrf_edgeai_output_propagate_neuton_f32,
	.interfaces.decode_outputs = nrf_edgeai_output_decode_regression_f32,

	.decoded_output.regression.meta.p_scale_min = MODEL_OUTPUT_SCALE_MIN,
	.decoded_output.regression.meta.p_scale_max = MODEL_OUTPUT_SCALE_MAX,
};

nrf_edgeai_t *model_ota_load(void)
{
	return &nrf_edgeai_;
}

#endif /* CONFIG_NRF_EDGEAI_REGRESSION_MODEL_OTA */
```
